# N32H7xx register map
Vendor: Nationstech Ltd.; File version: 1.0
CPU: CM7 r1p1, little endian, MPU, FPU, 4 interrupt priority bits
Registers are 32-bit, read-write, reset 0x0 unless marked. A register's access mark holds for its fields unless they carry their own. Offsets are from the block's base; [hi:lo] are bit positions; {n}, {i} and the like mark numbered series.

## GPV — Global programmer view
Base 0x51000000
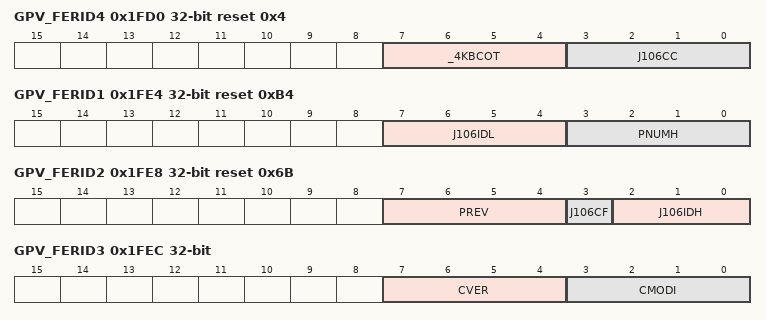
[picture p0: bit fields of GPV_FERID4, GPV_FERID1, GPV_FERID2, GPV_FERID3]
0x1FD0 GPV_FERID4 ro reset 0x4 — Periph ID 4
  [7:4] _4KBCOT, [3:0] J106CC
{0x1FC0+4i} GPV_FERID{i} ro (i=5..7) — Periph ID {i}
  [7:0] FERID{i}
0x1FE0 GPV_FERID0 ro — Periph ID 0
  [7:0] PNUML
0x1FE4 GPV_FERID1 ro reset 0xB4 — Periph ID 1
  [7:4] J106IDL, [3:0] PNUMH
0x1FE8 GPV_FERID2 ro reset 0x6B — Periph ID 2
  [7:4] PREV, [3] J106CF, [2:0] J106IDH
0x1FEC GPV_FERID3 ro — Periph ID 3
  [7:4] CVER, [3:0] CMODI
0x1FF0 GPV_COMID0 ro reset 0xD — Comp ID 0
  [7:0] PREAM1
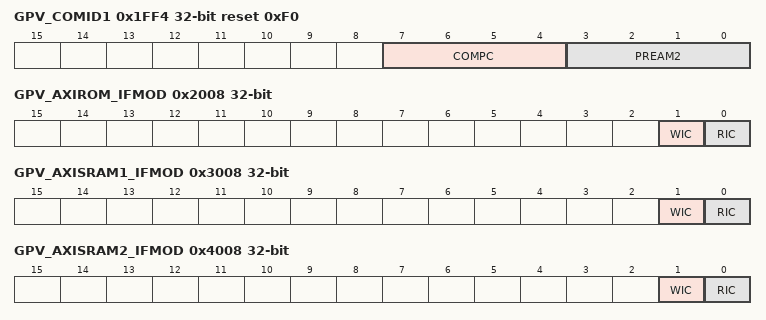
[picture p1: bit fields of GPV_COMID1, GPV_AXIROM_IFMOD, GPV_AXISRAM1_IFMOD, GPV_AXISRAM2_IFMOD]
0x1FF4 GPV_COMID1 ro reset 0xF0 — Comp ID 1
  [7:4] COMPC, [3:0] PREAM2
0x1FF8 GPV_COMID2 ro reset 0x5 — Comp ID 2
  [7:0] PREAM3
0x1FFC GPV_COMID3 ro — Comp ID 3
  [7:0] PREAM4
0x2008 GPV_AXIROM_IFMOD — AXI ROM issuing functionality modification register
  [1] WIC, [0] RIC
0x3008 GPV_AXISRAM1_IFMOD — AXISRAM1 issuing functionality modification register
  [1] WIC, [0] RIC
0x4008 GPV_AXISRAM2_IFMOD — AXISRAM2 issuing functionality modification register
  [1] WIC, [0] RIC
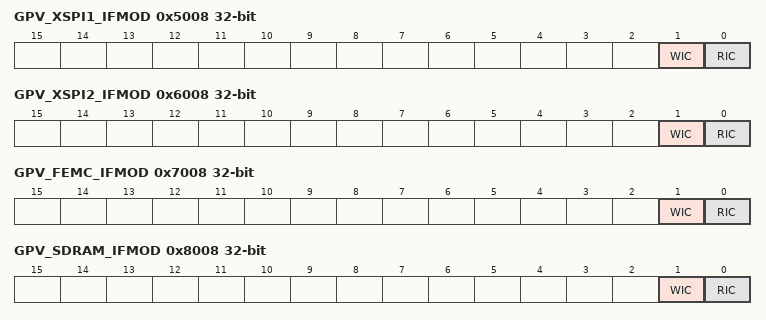
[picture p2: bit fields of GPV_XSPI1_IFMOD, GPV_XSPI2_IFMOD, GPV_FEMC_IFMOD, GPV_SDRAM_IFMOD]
0x5008 GPV_XSPI1_IFMOD — XSPI1 issuing functionality modification register
  [1] WIC, [0] RIC
0x6008 GPV_XSPI2_IFMOD — XSPI2 issuing functionality modification register
  [1] WIC, [0] RIC
0x7008 GPV_FEMC_IFMOD — FEMC issuing functionality modification register
  [1] WIC, [0] RIC
0x8008 GPV_SDRAM_IFMOD — SDRAM issuing functionality modification register
  [1] WIC, [0] RIC
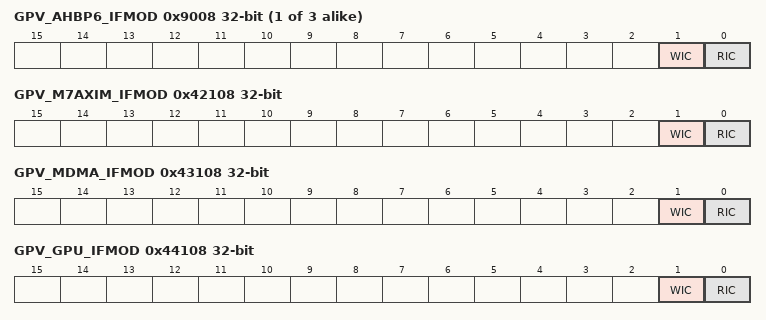
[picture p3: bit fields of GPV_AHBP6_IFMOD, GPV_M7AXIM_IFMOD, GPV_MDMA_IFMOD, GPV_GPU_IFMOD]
{0x3008+0x1000*i} GPV_AHBP{i}_IFMOD (i=6..8) — AHBP{i} issuing functionality modification register
  [1] WIC, [0] RIC
0x42100 GPV_M7AXIM_RQOS — CM7 AXIM read QoS
  [3:0] RQOS
0x42104 GPV_M7AXIM_WQOS — CM7 AXIM write QoS
  [3:0] WQOS
0x42108 GPV_M7AXIM_IFMOD — CM7 AXIM Issuing functionality modification register
  [1] WIC, [0] RIC
0x43100 GPV_MDMA_RQOS — MDMA read QoS
  [3:0] RQOS
0x43104 GPV_MDMA_WQOS — MDMA write QoS
  [3:0] WQOS
0x43108 GPV_MDMA_IFMOD — MDMA Issuing functionality modification register
  [1] WIC, [0] RIC
0x44100 GPV_GPU_RQOS — GPU read QoS
  [3:0] RQOS
0x44104 GPV_GPU_WQOS — GPU write QoS
  [3:0] WQOS
0x44108 GPV_GPU_IFMOD — GPU Issuing functionality modification register
  [1] WIC, [0] RIC
0x45100 GPV_LCDC_RQOS — LCDC read QoS
  [3:0] RQOS
0x45104 GPV_LCDC_WQOS — LCDC write QoS
  [3:0] WQOS
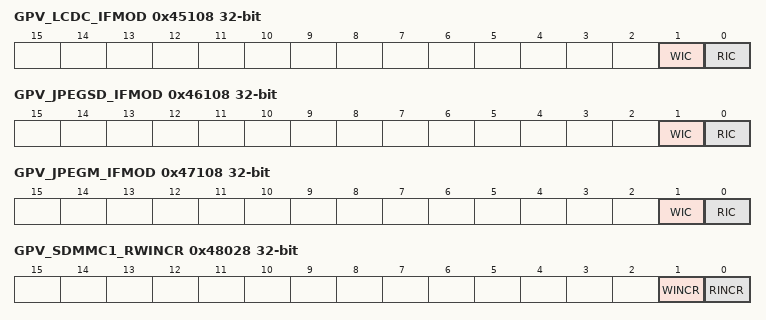
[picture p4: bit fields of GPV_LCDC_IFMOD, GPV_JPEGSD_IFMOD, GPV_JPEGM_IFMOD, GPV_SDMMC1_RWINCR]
0x45108 GPV_LCDC_IFMOD — LCDC Issuing functionality modification register
  [1] WIC, [0] RIC
0x46100 GPV_JPEGSD_RQOS — JPEG SGDMA read QoS
  [3:0] RQOS
0x46104 GPV_JPEGSD_WQOS — JPEG SGDMA write QoS
  [3:0] WQOS
0x46108 GPV_JPEGSD_IFMOD — JPEG SGDMA Issuing functionality modification register
  [1] WIC, [0] RIC
0x47100 GPV_JPEGM_RQOS — JPEG MEM read QoS
  [3:0] RQOS
0x47104 GPV_JPEGM_WQOS — JPEG MEM write QoS
  [3:0] WQOS
0x47108 GPV_JPEGM_IFMOD — JPEG MEM issuing functionality modification register
  [1] WIC, [0] RIC
0x48028 GPV_SDMMC1_RWINCR — SDMMC1 read write INCR register
  [1] WINCR, [0] RINCR
0x48100 GPV_SDMMC1_RQOS — SDMMC1 read QoS
  [3:0] RQOS
0x48104 GPV_SDMMC1_WQOS — SDMMC1 write QoS
  [3:0] WQOS
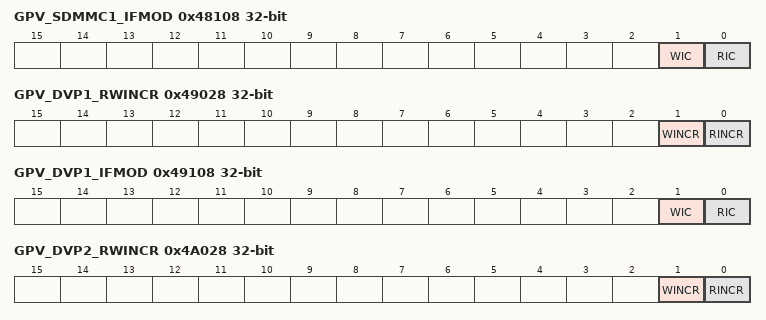
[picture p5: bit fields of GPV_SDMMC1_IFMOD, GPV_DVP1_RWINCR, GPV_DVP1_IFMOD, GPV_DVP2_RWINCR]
0x48108 GPV_SDMMC1_IFMOD — SDMMC1 issuing functionality modification register
  [1] WIC, [0] RIC
0x49028 GPV_DVP1_RWINCR — DVP1 read write INCR register
  [1] WINCR, [0] RINCR
0x49100 GPV_DVP1_RQOS — DVP1 read QoS
  [3:0] RQOS
0x49104 GPV_DVP1_WQOS — DVP1 write QoS
  [3:0] WQOS
0x49108 GPV_DVP1_IFMOD — DVP1 issuing functionality modification register
  [1] WIC, [0] RIC
0x4A028 GPV_DVP2_RWINCR — DVP2 read write INCR register
  [1] WINCR, [0] RINCR
0x4A100 GPV_DVP2_RQOS — DVP2 read QoS
  [3:0] RQOS
0x4A104 GPV_DVP2_WQOS — DVP2 write QoS
  [3:0] WQOS
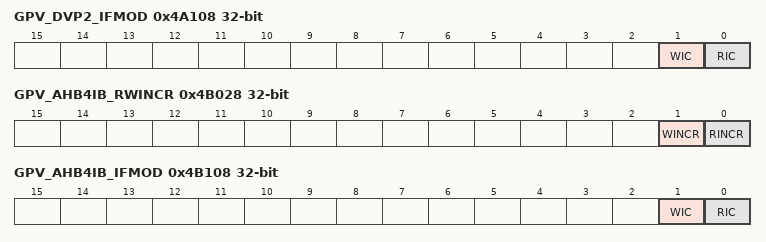
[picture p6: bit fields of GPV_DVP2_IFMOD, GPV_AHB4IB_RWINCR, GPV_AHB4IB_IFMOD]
0x4A108 GPV_DVP2_IFMOD — DVP2 Issuing functionality modification register
  [1] WIC, [0] RIC
0x4B024 GPV_AHB4IB_BM — AHB4 IB bypass merge register
  [0] BM
0x4B028 GPV_AHB4IB_RWINCR — AHB4 IB Read write INCR register
  [1] WINCR, [0] RINCR
0x4B100 GPV_AHB4IB_RQOS — AHB4 IB read QoS
  [3:0] RQOS
0x4B104 GPV_AHB4IB_WQOS — AHB4 IB write QoS
  [3:0] WQOS
0x4B108 GPV_AHB4IB_IFMOD — AHB4 IB Issuing functionality modification register
  [1] WIC, [0] RIC
